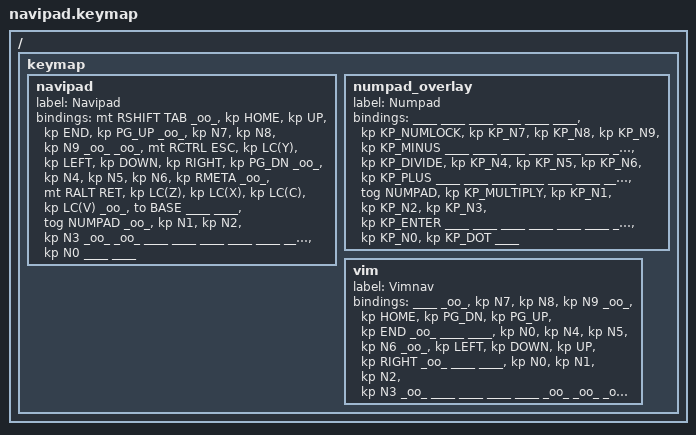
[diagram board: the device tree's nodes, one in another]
/ {
    keymap {
        navipad {
			label = "Navipad";
			bindings = <
//                ╭─────────┬───────┬───────┬───────┬───────┬───────╮                                     ╭─────┬─────┬─────┬─────┬─────┬─────╮
//                │  ⇧ │ ⭾  │  ---  │ HOME  │  UP   │  END  │ PG_UP │                                     │ --- │  7  │  8  │  9  │ --- │ --- │
//                ├─────────┼───────┼───────┼───────┼───────┼───────┤                                     ├─────┼─────┼─────┼─────┼─────┼─────┤
//                │  ⌃ │ ⎋  │ LC(Y) │ LEFT  │ DOWN  │ RIGHT │ PG_DN │                                     │ --- │  4  │  5  │  6  │  ◆  │ --- │
//                ├─────────┼───────┼───────┼───────┼───────┼───────┼──────────┬─────╮   ╭─────┬──────────┼─────┼─────┼─────┼─────┼─────┼─────┤
//                │  ⎇ │ ⏎  │ LC(Z) │ LC(X) │ LC(C) │ LC(V) │  ---  │ &to BASE │     │   │     │  NUMPAD │ --- │  1  │  2  │  3  │ --- │ --- │
//                ╰─────────┴───────┴───────┼───────┼───────┼───────┼──────────┼─────┤   ├─────┼──────────┼─────┼─────┼─────┼─────┴─────┴─────╯
//                                          │       │       │       │          │     │   │     │          │  0  │     │     │                  
//                                          ╰───────┴───────┴───────┴──────────┴─────╯   ╰─────┴──────────┴─────┴─────┴─────╯                  
              &mt RSHIFT TAB   _oo_        &kp HOME    &kp UP      &kp END     &kp PG_UP                                              _oo_     &kp N7   &kp N8   &kp N9   _oo_        _oo_
              &mt RCTRL ESC    &kp LC(Y)   &kp LEFT    &kp DOWN    &kp RIGHT   &kp PG_DN                                              _oo_     &kp N4   &kp N5   &kp N6   &kp RMETA   _oo_
              &mt RALT RET     &kp LC(Z)   &kp LC(X)   &kp LC(C)   &kp LC(V)   _oo_        &to BASE   ____       ____   &tog NUMPAD   _oo_     &kp N1   &kp N2   &kp N3   _oo_        _oo_
                                                       ____        ____        ____        ____       ____       ____   ____          &kp N0   ____     ____                              
            >;
        };
        numpad_overlay {
			label = "Numpad";
			bindings = <
//                ╭─────┬─────┬─────┬─────┬─────┬─────╮                                ╭──────────┬─────┬─────┬─────┬───────┬─────╮
//                │     │     │     │     │     │     │                                │ NUMLOCK  │  7  │  8  │  9  │   -   │     │
//                ├─────┼─────┼─────┼─────┼─────┼─────┤                                ├──────────┼─────┼─────┼─────┼───────┼─────┤
//                │     │     │     │     │     │     │                                │  DIVIDE  │  4  │  5  │  6  │   +   │     │
//                ├─────┼─────┼─────┼─────┼─────┼─────┼─────┬─────╮   ╭─────┬──────────┼──────────┼─────┼─────┼─────┼───────┼─────┤
//                │     │     │     │     │     │     │     │     │   │     │  NUMPAD │ MULTIPLY │  1  │  2  │  3  │ ENTER │     │
//                ╰─────┴─────┴─────┼─────┼─────┼─────┼─────┼─────┤   ├─────┼──────────┼──────────┼─────┼─────┼─────┴───────┴─────╯
//                                  │     │     │     │     │     │   │     │          │    0     │  .  │     │                    
//                                  ╰─────┴─────┴─────┴─────┴─────╯   ╰─────┴──────────┴──────────┴─────┴─────╯                    
              ____   ____   ____   ____   ____   ____                                          &kp KP_NUMLOCK    &kp KP_N7    &kp KP_N8   &kp KP_N9   &kp KP_MINUS   ____
              ____   ____   ____   ____   ____   ____                                          &kp KP_DIVIDE     &kp KP_N4    &kp KP_N5   &kp KP_N6   &kp KP_PLUS    ____
              ____   ____   ____   ____   ____   ____   ____   ____       ____   &tog NUMPAD   &kp KP_MULTIPLY   &kp KP_N1    &kp KP_N2   &kp KP_N3   &kp KP_ENTER   ____
                                   ____   ____   ____   ____   ____       ____   ____          &kp KP_N0         &kp KP_DOT   ____                                       
            >;
        };
		vim {
			label = "Vimnav";
			bindings = <
//                ╭─────┬─────┬─────┬─────┬─────┬─────╮                           ╭──────┬───────┬───────┬───────┬─────┬─────╮
//                │     │ --- │  7  │  8  │  9  │ --- │                           │ HOME │ PG_DN │ PG_UP │  END  │ --- │     │
//                ├─────┼─────┼─────┼─────┼─────┼─────┤                           ├──────┼───────┼───────┼───────┼─────┼─────┤
//                │     │  0  │  4  │  5  │  6  │ --- │                           │ LEFT │ DOWN  │  UP   │ RIGHT │ --- │     │
//                ├─────┼─────┼─────┼─────┼─────┼─────┼─────┬─────╮   ╭─────┬─────┼──────┼───────┼───────┼───────┼─────┼─────┤
//                │     │  0  │  1  │  2  │  3  │ --- │     │     │   │     │     │ ---  │  ---  │  ---  │  ---  │ --- │     │
//                ╰─────┴─────┴─────┼─────┼─────┼─────┼─────┼─────┤   ├─────┼─────┼──────┼───────┼───────┼───────┴─────┴─────╯
//                                  │     │     │     │     │     │   │     │     │      │       │       │                    
//                                  ╰─────┴─────┴─────┴─────┴─────╯   ╰─────┴─────┴──────┴───────┴───────╯                    
              ____   _oo_     &kp N7   &kp N8   &kp N9   _oo_                                   &kp HOME   &kp PG_DN   &kp PG_UP   &kp END     _oo_   ____
              ____   &kp N0   &kp N4   &kp N5   &kp N6   _oo_                                   &kp LEFT   &kp DOWN    &kp UP      &kp RIGHT   _oo_   ____
              ____   &kp N0   &kp N1   &kp N2   &kp N3   _oo_   ____   ____       ____   ____   _oo_       _oo_        _oo_        _oo_        _oo_   ____
                                       ____     ____     ____   ____   ____       ____   ____   ____       ____        ____                               
            >;
        };
    };
};
